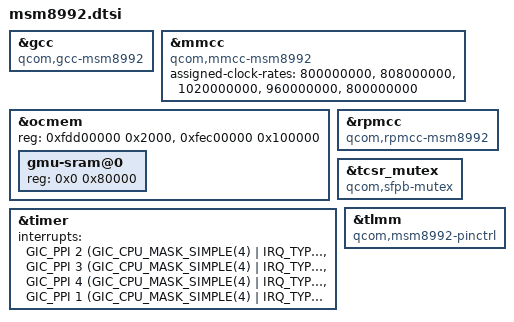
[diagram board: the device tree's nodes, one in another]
// SPDX-License-Identifier: GPL-2.0-only
/* Copyright (c) 2013-2016, The Linux Foundation. All rights reserved.
 */

#include "msm8994.dtsi"

/* 8992 only features 2 A57 cores. */
/delete-node/ &CPU6;
/delete-node/ &CPU7;
/delete-node/ &cpu6_map;
/delete-node/ &cpu7_map;

&gcc {
	compatible = "qcom,gcc-msm8992";
};

&mmcc {
	compatible = "qcom,mmcc-msm8992";

	assigned-clock-rates = <800000000>,
			       <808000000>,
			       <1020000000>,
			       <960000000>,
			       <800000000>;
};

&ocmem {
	reg = <0xfdd00000 0x2000>, <0xfec00000 0x100000>;

	gmu-sram@0 {
		reg = <0x0 0x80000>;
	};
};

&rpmcc {
	compatible = "qcom,rpmcc-msm8992", "qcom,rpmcc";
};

&tcsr_mutex {
	compatible = "qcom,sfpb-mutex";
};

&timer {
	interrupts = <GIC_PPI 2 (GIC_CPU_MASK_SIMPLE(4) | IRQ_TYPE_LEVEL_LOW)>,
			     <GIC_PPI 3 (GIC_CPU_MASK_SIMPLE(4) | IRQ_TYPE_LEVEL_LOW)>,
			     <GIC_PPI 4 (GIC_CPU_MASK_SIMPLE(4) | IRQ_TYPE_LEVEL_LOW)>,
			     <GIC_PPI 1 (GIC_CPU_MASK_SIMPLE(4) | IRQ_TYPE_LEVEL_LOW)>;
};

&tlmm {
	compatible = "qcom,msm8992-pinctrl";
};
